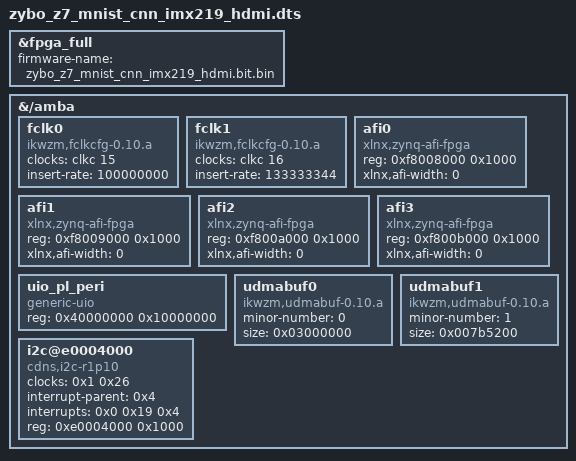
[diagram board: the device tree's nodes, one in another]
/dts-v1/; /plugin/;

/ {
    fragment@0 {  
        target = <&fpga_full>;
        __overlay__ {
            #address-cells = <1>;
            #size-cells = <1>;

            firmware-name = "zybo_z7_mnist_cnn_imx219_hdmi.bit.bin";
        };
    };

    fragment@1 {
        target-path = "/amba";
        __overlay__ {
            fclk0 {
                compatible  = "ikwzm,fclkcfg-0.10.a";
                clocks      = <&clkc 15>;
                insert-rate = "100000000";
            };
            fclk1 {
                compatible  = "ikwzm,fclkcfg-0.10.a";
                clocks      = <&clkc 16>;
/*              insert-rate = "125000000"; */
                insert-rate = "133333344";
            };

            afi0: afi0 {
                compatible = "xlnx,zynq-afi-fpga";
                reg = <0xf8008000 0x1000>;
                xlnx,afi-width = <0>;  /* 0:64bit, 1:32bit */
            };
            afi1: afi1 {
                compatible = "xlnx,zynq-afi-fpga";
                reg = <0xf8009000 0x1000>;
                xlnx,afi-width = <0>;  /* 0:64bit, 1:32bit */
            };
            afi2: afi2 {
                compatible = "xlnx,zynq-afi-fpga";
                reg = <0xf800a000 0x1000>;
                xlnx,afi-width = <0>;  /* 0:64bit, 1:32bit */
            };
            afi3: afi3 {
                compatible = "xlnx,zynq-afi-fpga";
                reg = <0xf800b000 0x1000>;
                xlnx,afi-width = <0>;  /* 0:64bit, 1:32bit */
            };
        };
    };

    fragment@2 {
        target-path = "/amba";
        __overlay__ {
            #address-cells = <0x1>;
            #size-cells = <0x1>;
            
            uio_pl_peri {
                compatible = "generic-uio";
                reg = <0x40000000 0x10000000>;
            };

            udmabuf0 {
                compatible = "ikwzm,udmabuf-0.10.a";
                minor-number = <0>;
                size = <0x03000000>;
            };

            udmabuf1 {
                compatible = "ikwzm,udmabuf-0.10.a";
                minor-number = <1>;
                size = <0x007b5200>;
            };
        };
    };


    fragment@3 {
        target-path = "/amba";
        __overlay__ {
    		i2c@e0004000 {
                compatible = "cdns,i2c-r1p10";
                status = "okay";
                clocks = <0x1 0x26>;
                interrupt-parent = <0x4>;
                interrupts = <0x0 0x19 0x4>;
                reg = <0xe0004000 0x1000>;
                #address-cells = <0x1>;
                #size-cells = <0x0>;
            };
        };
    };
};


